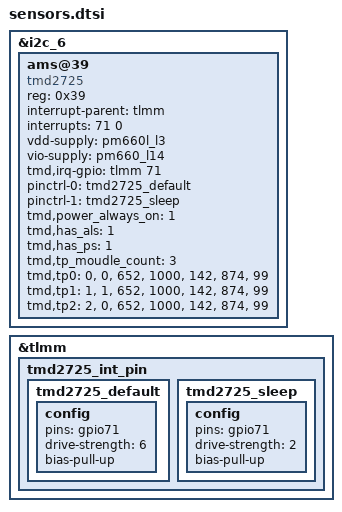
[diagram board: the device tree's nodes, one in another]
/*
 * Copyright (c) 2015-2016, The Linux Foundation. All rights reserved.
 *
 * This program is free software; you can redistribute it and/or modify
 * it under the terms of the GNU General Public License version 2 and
 * only version 2 as published by the Free Software Foundation.
 *
 * This program is distributed in the hope that it will be useful,
 * but WITHOUT ANY WARRANTY; without even the implied warranty of
 * MERCHANTABILITY or FITNESS FOR A PARTICULAR PURPOSE.  See the
 * GNU General Public License for more details.
 */


/*
 * Add nubia sensors
 */
&i2c_6 {
	ams@39 {
		compatible = "tmd2725";
		reg = <0x39>;
		interrupt-parent = <&tlmm>;
		interrupts = <71 0>;
		vdd-supply = <&pm660l_l3>;
		vio-supply = <&pm660_l14>;
		tmd,irq-gpio = <&tlmm 71 0x00>;
		pinctrl-names = "tmd2725_default","tmd2725_sleep";
		pinctrl-0 = <&tmd2725_default>;
		pinctrl-1 = <&tmd2725_sleep>;
		tmd,power_always_on = <1>;
		tmd,has_als = <1>;
		tmd,has_ps = <1>;
		tmd,tp_moudle_count = <3>;
		//[module_id] [which_seg] [d_factor] ch0[1] ch1[0] ch0[1] ch1[0]
		tmd,tp0 = "0","0","652","1000","142","874","99";
		//[module_id] [which_seg] [d_factor] ch0[1] ch1[0] ch0[1] ch1[0]
		tmd,tp1 = "1","1","652","1000","142","874","99";
		//[module_id] [which_seg] [d_factor] ch0[1] ch1[0] ch0[1] ch1[0]
		tmd,tp2 = "2","0","652","1000","142","874","99";
	};
};

&tlmm {
	tmd2725_int_pin {
		tmd2725_default: tmd2725_default {
		                config {
                            pins = "gpio71";
			                drive-strength = <6>;
		                    bias-pull-up;
                                };
		};
		tmd2725_sleep: tmd2725_sleep {
		                config {
                            pins = "gpio71";
				            drive-strength = <2>;
				            bias-pull-up;
                                };
		};
	};
};




